# PY32F303 register map
Vendor: PUYA Co.Ltd; Series: ARMCM4; File version: 1.2
CPU: CM4 r0p1, little endian, MPU, FPU, 4 interrupt priority bits
Registers are 32-bit, read-write, reset 0x0 unless marked. A register's access mark holds for its fields unless they carry their own. Offsets are from the block's base; [hi:lo] are bit positions; {n}, {i} and the like mark numbered series.

## RTC
Base 0x40002800
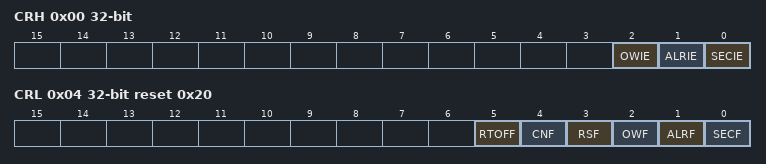
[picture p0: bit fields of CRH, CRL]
0x00 CRH
  [2] OWIE, [1] ALRIE, [0] SECIE
0x04 CRL reset 0x20
  [5] RTOFF ro, [4] CNF, [3] RSF, [2] OWF, [1] ALRF, [0] SECF
0x08 PRLH wo
  [3:0] PRL
0x0C PRLL wo reset 0x8000
  [15:0] PRL
0x10 DIVH ro
  [15:0] DIV
0x14 DIVL ro reset 0x8000
  [15:0] DIV
0x18 CNTH
  [15:0] RTC_CNT
0x1C CNTL
  [15:0] RTC_CNT
0x20 ALRH reset 0xFFFF
  [15:0] RTC_ALR
0x24 ALRL reset 0xFFFF
  [15:0] RTC_ALR

## SDIO
Base 0x40018000
0x00 POWER
  [0] PWRCTRL
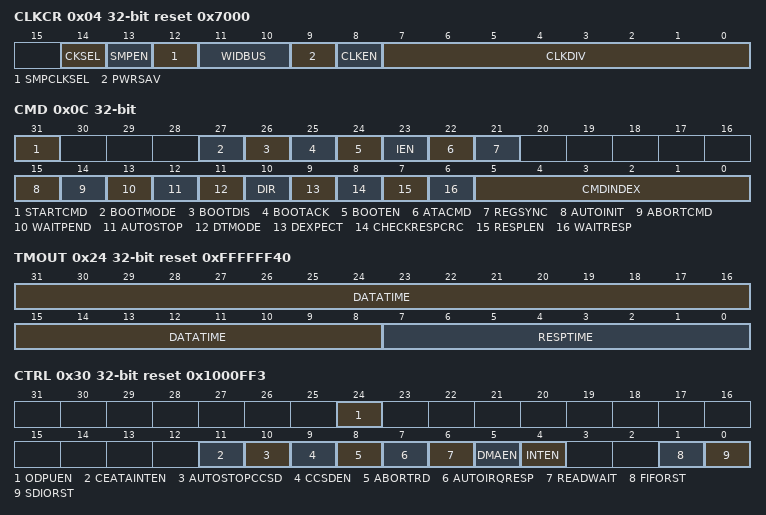
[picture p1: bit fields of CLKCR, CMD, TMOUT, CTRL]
0x04 CLKCR reset 0x7000
  [14] CKSEL, [13] SMPEN, [12] SMPCLKSEL, [11:10] WIDBUS, [9] PWRSAV, [8] CLKEN, [7:0] CLKDIV
0x08 ARG
  [31:0] CMDARG
0x0C CMD
  [31] STARTCMD, [27] BOOTMODE, [26] BOOTDIS, [25] BOOTACK, [24] BOOTEN, [23] IEN, [22] ATACMD, [21] REGSYNC, [15] AUTOINIT, [14] ABORTCMD, [13] WAITPEND, [12] AUTOSTOP, [11] DTMODE, [10] DIR, [9] DEXPECT, [8] CHECKRESPCRC, [7] RESPLEN, [6] WAITRESP, [5:0] CMDINDEX
0x10 RESPCMD ro
  [5:0] RESPCMD
{0x14+4i} RESP{i} ro (i=0..3)
  [31:0] CARDSTATUS{i+1}
0x24 TMOUT reset 0xFFFFFF40
  [31:8] DATATIME, [7:0] RESPTIME
0x28 BLKSIZ reset 0x200
  [15:0] DBLOCKSIZE
0x2C DLEN
  [31:0] DATALENGTH
0x30 CTRL reset 0x1000FF3
  [24] ODPUEN, [11] CEATAINTEN, [10] AUTOSTOPCCSD, [9] CCSDEN, [8] ABORTRD, [7] AUTOIRQRESP, [6] READWAIT, [5] DMAEN, [4] INTEN, [1] FIFORST, [0] SDIORST
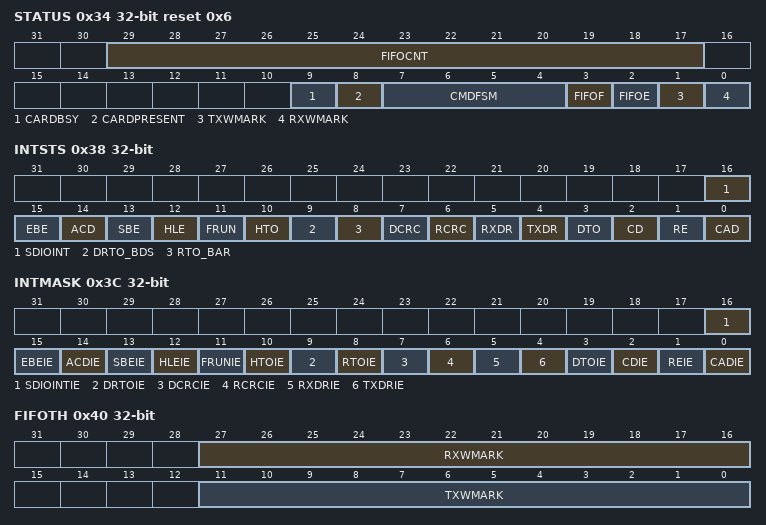
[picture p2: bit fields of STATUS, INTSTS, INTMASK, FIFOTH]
0x34 STATUS ro reset 0x6
  [29:17] FIFOCNT, [9] CARDBSY, [8] CARDPRESENT, [7:4] CMDFSM, [3] FIFOF, [2] FIFOE, [1] TXWMARK, [0] RXWMARK
0x38 INTSTS
  [16] SDIOINT, [15] EBE, [14] ACD, [13] SBE, [12] HLE, [11] FRUN, [10] HTO, [9] DRTO_BDS, [8] RTO_BAR, [7] DCRC, [6] RCRC, [5] RXDR, [4] TXDR, [3] DTO, [2] CD, [1] RE, [0] CAD
0x3C INTMASK
  [16] SDIOINTIE, [15] EBEIE, [14] ACDIE, [13] SBEIE, [12] HLEIE, [11] FRUNIE, [10] HTOIE, [9] DRTOIE, [8] RTOIE, [7] DCRCIE, [6] RCRCIE, [5] RXDRIE, [4] TXDRIE, [3] DTOIE, [2] CDIE, [1] REIE, [0] CADIE
0x40 FIFOTH
  [27:16] RXWMARK, [11:0] TXWMARK
0x44 TCBCNT ro
0x48 TBBCNT ro

## SPI1 — desc SPI
Base 0x40013000
Same registers: SPI2 0x40003800, SPI3 0x40003C00
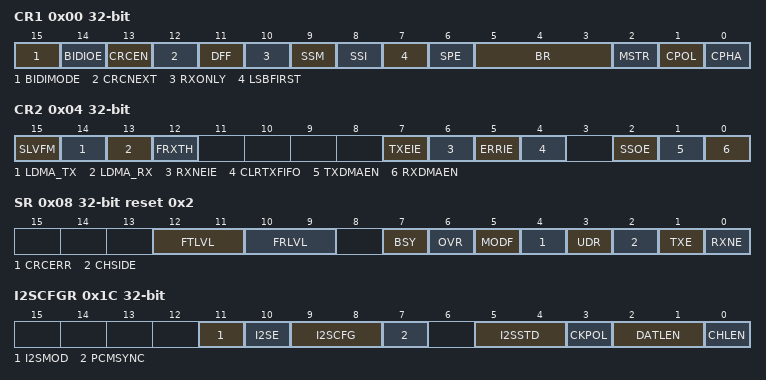
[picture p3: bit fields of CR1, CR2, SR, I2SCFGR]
0x00 CR1
  [15] BIDIMODE, [14] BIDIOE, [13] CRCEN, [12] CRCNEXT, [11] DFF, [10] RXONLY, [9] SSM, [8] SSI, [7] LSBFIRST, [6] SPE, [5:3] BR, [2] MSTR, [1] CPOL, [0] CPHA
0x04 CR2 (reset mask 0xE7)
  [15] SLVFM, [14] LDMA_TX, [13] LDMA_RX, [12] FRXTH, [7] TXEIE, [6] RXNEIE, [5] ERRIE, [4] CLRTXFIFO, [2] SSOE, [1] TXDMAEN, [0] RXDMAEN
0x08 SR reset 0x2
  [12:11] FTLVL ro, [10:9] FRLVL ro, [7] BSY ro, [6] OVR ro, [5] MODF ro, [4] CRCERR, [3] UDR ro, [2] CHSIDE ro, [1] TXE ro, [0] RXNE ro
0x0C DR
  [15:0] DR
0x10 CRCPR reset 0x7
  [15:0] CRCPOLY
0x14 RXCRCR ro
  [15:0] RXCRC
0x18 TXCRCR ro
  [15:0] TXCRC
0x1C I2SCFGR
  [11] I2SMOD, [10] I2SE, [9:8] I2SCFG, [7] PCMSYNC, [5:4] I2SSTD, [3] CKPOL, [2:1] DATLEN, [0] CHLEN
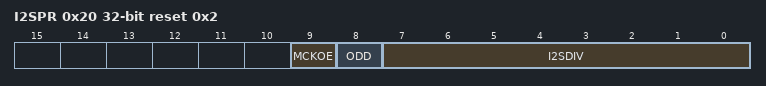
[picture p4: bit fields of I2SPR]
0x20 I2SPR reset 0x2
  [9] MCKOE, [8] ODD, [7:0] I2SDIV

## SYSCFG
Base 0x40010000
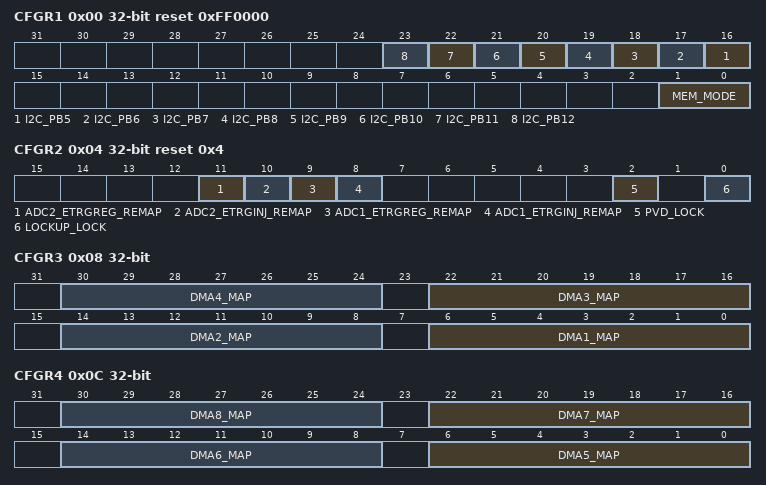
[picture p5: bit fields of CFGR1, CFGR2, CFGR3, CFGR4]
0x00 CFGR1 reset 0xFF0000
  [n+11] I2C_PB{n} (n=5..12), [1:0] MEM_MODE
0x04 CFGR2 reset 0x4 (reset mask 0x5)
  [11] ADC2_ETRGREG_REMAP, [10] ADC2_ETRGINJ_REMAP, [9] ADC1_ETRGREG_REMAP, [8] ADC1_ETRGINJ_REMAP, [2] PVD_LOCK, [0] LOCKUP_LOCK
0x08 CFGR3
  [8n-2:8n-8] DMA{n}_MAP (n=1..4)
0x0C CFGR4
  [8n-34:8n-40] DMA{n}_MAP (n=5..8)
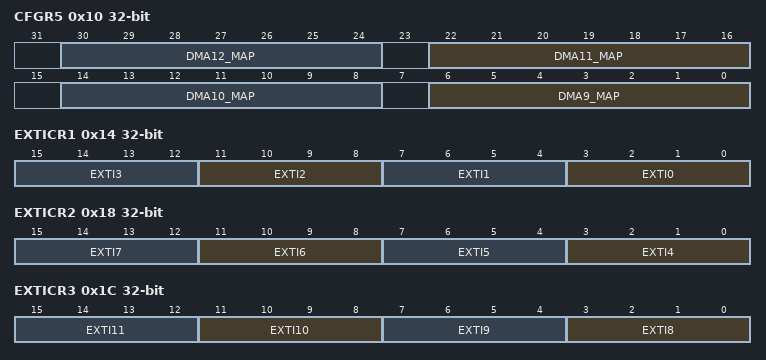
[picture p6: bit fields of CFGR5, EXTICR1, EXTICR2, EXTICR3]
0x10 CFGR5
  [8n-66:8n-72] DMA{n}_MAP (n=9..12)
0x14 EXTICR1
  [4n+3:4n] EXTI{n} (n=0..3)
0x18 EXTICR2
  [4n-13:4n-16] EXTI{n} (n=4..7)
0x1C EXTICR3
  [4n-29:4n-32] EXTI{n} (n=8..11)
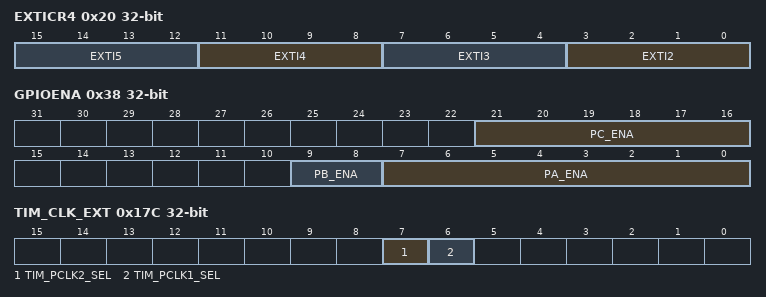
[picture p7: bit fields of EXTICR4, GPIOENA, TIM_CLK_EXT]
0x20 EXTICR4
  [4n-5:4n-8] EXTI{n} (n=2..5)
0x24 PAENS
  [15:0] PA_ENS
0x28 PBENS
  [15:0] PB_ENS
0x2C PCENS
  [15:0] PC_ENS
0x30 PDENS
  [15:0] PD_ENS
0x34 PEENS
  [15:0] PE_ENS
0x38 GPIOENA
  [21:16] PC_ENA, [9:8] PB_ENA, [7:0] PA_ENA
0x17C TIM_CLK_EXT — desc GPIOENA
  [7] TIM_PCLK2_SEL, [6] TIM_PCLK1_SEL
